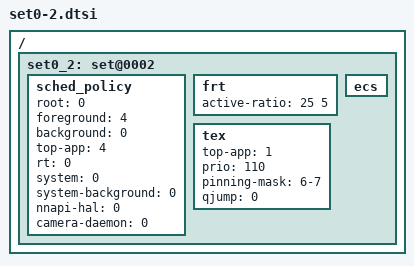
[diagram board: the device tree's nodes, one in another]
/ {
	/* normal mode - app boost */
	set0_2: set@0002 {
		sched_policy {
			root = <0>;
			foreground = <4>;
			background = <0>;
			top-app = <4>;
			rt = <0>;
			system = <0>;
			system-background = <0>;
			nnapi-hal = <0>;
			camera-daemon = <0>;
		};

		frt {	   			/* LIT BIG */
			active-ratio 		= < 25   5>;
		};

		ecs { };

		tex {
			top-app		= <1>;
			prio		= <110>;
			pinning-mask	= "6-7";
			qjump		= <0>;
		};
	};
};
